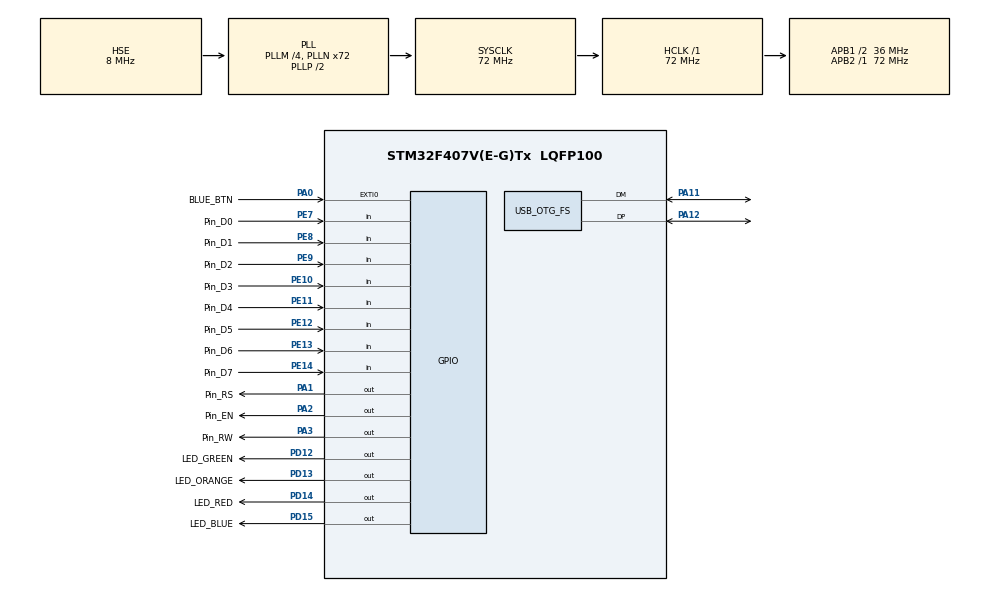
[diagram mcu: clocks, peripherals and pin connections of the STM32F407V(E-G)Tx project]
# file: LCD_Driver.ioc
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Mcu.Family=STM32F4
Mcu.Name=STM32F407V(E-G)Tx
Mcu.Package=LQFP100
NVIC.OTG_FS_IRQn=true\:0\:0\:false\:false\:true\:true\:true\:true
NVIC.PriorityGroup=NVIC_PRIORITYGROUP_0
PA0-WKUP.GPIO_Label=BLUE_BTN
PA0-WKUP.GPIO_ModeDefaultEXTI=GPIO_MODE_EVT_RISING
PA0-WKUP.GPIO_PuPd=GPIO_NOPULL
PA0-WKUP.Signal=GPXTI0
PA1.GPIO_Label=Pin_RS
PA1.Signal=GPIO_Output
PA11.Mode=Device_Only
PA11.Signal=USB_OTG_FS_DM
PA12.Mode=Device_Only
PA12.Signal=USB_OTG_FS_DP
PA2.GPIO_Label=Pin_EN
PA2.Signal=GPIO_Output
PA3.GPIO_Label=Pin_RW
PA3.Signal=GPIO_Output
PD12.GPIO_Label=LED_GREEN
PD12.GPIO_PuPd=GPIO_NOPULL
PD12.GPIO_Speed=GPIO_SPEED_FREQ_LOW
PD12.Signal=GPIO_Output
PD13.GPIO_Label=LED_ORANGE
PD13.GPIO_PuPd=GPIO_NOPULL
PD13.GPIO_Speed=GPIO_SPEED_FREQ_LOW
PD13.Signal=GPIO_Output
PD14.GPIO_Label=LED_RED
PD14.GPIO_PuPd=GPIO_NOPULL
PD14.GPIO_Speed=GPIO_SPEED_FREQ_LOW
PD14.Signal=GPIO_Output
PD15.GPIO_Label=LED_BLUE
PD15.GPIO_PuPd=GPIO_NOPULL
PD15.GPIO_Speed=GPIO_SPEED_FREQ_LOW
PD15.Signal=GPIO_Output
PE10.GPIO_Label=Pin_D3
PE10.Signal=GPIO_Input
PE11.GPIO_Label=Pin_D4
PE11.Signal=GPIO_Input
PE12.GPIO_Label=Pin_D5
PE12.Signal=GPIO_Input
PE13.GPIO_Label=Pin_D6
PE13.Signal=GPIO_Input
PE14.GPIO_Label=Pin_D7
PE14.Signal=GPIO_Input
PE7.GPIO_Label=Pin_D0
PE7.Signal=GPIO_Input
PE8.GPIO_Label=Pin_D1
PE8.Signal=GPIO_Input
PE9.GPIO_Label=Pin_D2
PE9.Signal=GPIO_Input
PH0-OSC_IN.Mode=HSE-External-Oscillator
PH0-OSC_IN.Signal=RCC_OSC_IN
PH1-OSC_OUT.Mode=HSE-External-Oscillator
PH1-OSC_OUT.Signal=RCC_OSC_OUT
ProjectManager.HeapSize=0x200
ProjectManager.StackSize=0x400
ProjectManager.TargetToolchain=STM32CubeIDE
RCC.48MHZClocksFreq_Value=48000000
RCC.AHBFreq_Value=72000000
RCC.APB1CLKDivider=RCC_HCLK_DIV2
RCC.APB1Freq_Value=36000000
RCC.APB1TimFreq_Value=72000000
RCC.APB2Freq_Value=72000000
RCC.APB2TimFreq_Value=72000000
RCC.CortexFreq_Value=72000000
RCC.HCLKFreq_Value=72000000
RCC.HSE_VALUE=8000000
RCC.HSI_VALUE=16000000
RCC.LSE_VALUE=32768
RCC.PLLM=4
RCC.PLLN=72
RCC.PLLQ=3
RCC.SYSCLKFreq_VALUE=72000000
RCC.SYSCLKSource=RCC_SYSCLKSOURCE_PLLCLK
RCC.VCOOutputFreq_Value=144000000
USB_DEVICE.CLASS_NAME_FS=CDC
USB_DEVICE.VirtualMode-CDC_FS=Cdc
USB_DEVICE.VirtualModeFS=Cdc_FS
USB_OTG_FS.VirtualMode=Device_Only
VP_USB_DEVICE_VS_USB_DEVICE_CDC_FS.Mode=CDC_FS
board=STM32F407G-DISC1

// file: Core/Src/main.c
/* USER CODE BEGIN Header */
/**
  ******************************************************************************
  * @file           : main.c
  * @brief          : Main program body
  ******************************************************************************
  * @attention
  *
  * Copyright (c) 2026 STMicroelectronics.
  * All rights reserved.
  *
  * This software is licensed under terms that can be found in the LICENSE file
  * in the root directory of this software component.
  * If no LICENSE file comes with this software, it is provided AS-IS.
  *
  ******************************************************************************
  */
/* USER CODE END Header */
#include <lcd_HD44780U.h>
#include "main.h"
#include "usb_device.h"

/* USER CODE BEGIN Includes */
#include <string.h>
#include "usbd_cdc_if.h"
/* USER CODE END Includes */

void SystemClock_Config(void);
static void MX_GPIO_Init(void);
/* USER CODE BEGIN PFP */
void USBD_CDC_Receive(uint8_t* buf, uint32_t* len);
/* USER CODE END PFP */

/* USER CODE BEGIN 0 */
void USBD_CDC_Receive(uint8_t* buf, uint32_t* len)
{
	//IMPORTANT: This function is run in an interrupt. Do not call HAL_Delay, any
	//other blocking operation or any heavy processing. For any of these, best course
	//of action is to copy the result into a buffer and process it in main(). For light
	//processing, doing it in this function is fine.
	CDC_Transmit_FS(buf, *len);
}

/* USER CODE END 0 */

int main(void)
{

  /* MCU Configuration--------------------------------------------------------*/

  /* Reset of all peripherals, Initializes the Flash interface and the Systick. */
  HAL_Init();

  /* Configure the system clock */
  SystemClock_Config();

  /* Initialize all configured peripherals */
  MX_GPIO_Init();
  MX_USB_DEVICE_Init();

  /* Infinite loop */
  /* USER CODE BEGIN WHILE */

  Init16x2LCD();

  while (1)
  {
    /* USER CODE END WHILE */

  }
}

void SystemClock_Config(void)
{
  RCC_OscInitTypeDef RCC_OscInitStruct = {0};
  RCC_ClkInitTypeDef RCC_ClkInitStruct = {0};

  /** Configure the main internal regulator output voltage
  */
  __HAL_RCC_PWR_CLK_ENABLE();
  __HAL_PWR_VOLTAGESCALING_CONFIG(PWR_REGULATOR_VOLTAGE_SCALE1);

  /** Initializes the RCC Oscillators according to the specified parameters
  * in the RCC_OscInitTypeDef structure.
  */
  RCC_OscInitStruct.OscillatorType = RCC_OSCILLATORTYPE_HSE;
  RCC_OscInitStruct.HSEState = RCC_HSE_ON;
  RCC_OscInitStruct.PLL.PLLState = RCC_PLL_ON;
  RCC_OscInitStruct.PLL.PLLSource = RCC_PLLSOURCE_HSE;
  RCC_OscInitStruct.PLL.PLLM = 4;
  RCC_OscInitStruct.PLL.PLLN = 72;
  RCC_OscInitStruct.PLL.PLLP = RCC_PLLP_DIV2;
  RCC_OscInitStruct.PLL.PLLQ = 3;
  if (HAL_RCC_OscConfig(&RCC_OscInitStruct) != HAL_OK)
  {
    Error_Handler();
  }

  /** Initializes the CPU, AHB and APB buses clocks
  */
  RCC_ClkInitStruct.ClockType = RCC_CLOCKTYPE_HCLK|RCC_CLOCKTYPE_SYSCLK
                              |RCC_CLOCKTYPE_PCLK1|RCC_CLOCKTYPE_PCLK2;
  RCC_ClkInitStruct.SYSCLKSource = RCC_SYSCLKSOURCE_PLLCLK;
  RCC_ClkInitStruct.AHBCLKDivider = RCC_SYSCLK_DIV1;
  RCC_ClkInitStruct.APB1CLKDivider = RCC_HCLK_DIV2;
  RCC_ClkInitStruct.APB2CLKDivider = RCC_HCLK_DIV1;

  if (HAL_RCC_ClockConfig(&RCC_ClkInitStruct, FLASH_LATENCY_2) != HAL_OK)
  {
    Error_Handler();
  }
}

static void MX_GPIO_Init(void)
{
  GPIO_InitTypeDef GPIO_InitStruct = {0};

  /* GPIO Ports Clock Enable */
  __HAL_RCC_GPIOH_CLK_ENABLE();
  __HAL_RCC_GPIOA_CLK_ENABLE();
  __HAL_RCC_GPIOE_CLK_ENABLE();
  __HAL_RCC_GPIOD_CLK_ENABLE();

  /*Configure GPIO pin Output Level */
  HAL_GPIO_WritePin(GPIOA, Pin_RS_Pin|Pin_EN_Pin|Pin_RW_Pin, GPIO_PIN_RESET);

  /*Configure GPIO pin Output Level */
  HAL_GPIO_WritePin(GPIOD, LED_GREEN_Pin|LED_ORANGE_Pin|LED_RED_Pin|LED_BLUE_Pin, GPIO_PIN_RESET);

  /*Configure GPIO pin : BLUE_BTN_Pin */
  GPIO_InitStruct.Pin = BLUE_BTN_Pin;
  GPIO_InitStruct.Mode = GPIO_MODE_EVT_RISING;
  GPIO_InitStruct.Pull = GPIO_NOPULL;
  HAL_GPIO_Init(BLUE_BTN_GPIO_Port, &GPIO_InitStruct);

  /*Configure GPIO pins : Pin_RS_Pin Pin_EN_Pin Pin_RW_Pin */
  GPIO_InitStruct.Pin = Pin_RS_Pin|Pin_EN_Pin|Pin_RW_Pin;
  GPIO_InitStruct.Mode = GPIO_MODE_OUTPUT_PP;
  GPIO_InitStruct.Pull = GPIO_NOPULL;
  GPIO_InitStruct.Speed = GPIO_SPEED_FREQ_LOW;
  HAL_GPIO_Init(GPIOA, &GPIO_InitStruct);

  /*Configure GPIO pins : Pin_D0_Pin Pin_D1_Pin Pin_D2_Pin Pin_D3_Pin
                           Pin_D4_Pin Pin_D5_Pin Pin_D6_Pin Pin_D7_Pin */
  GPIO_InitStruct.Pin = Pin_D0_Pin|Pin_D1_Pin|Pin_D2_Pin|Pin_D3_Pin
                          |Pin_D4_Pin|Pin_D5_Pin|Pin_D6_Pin|Pin_D7_Pin;
  GPIO_InitStruct.Mode = GPIO_MODE_INPUT;
  GPIO_InitStruct.Pull = GPIO_NOPULL;
  HAL_GPIO_Init(GPIOE, &GPIO_InitStruct);

  /*Configure GPIO pins : LED_GREEN_Pin LED_ORANGE_Pin LED_RED_Pin LED_BLUE_Pin */
  GPIO_InitStruct.Pin = LED_GREEN_Pin|LED_ORANGE_Pin|LED_RED_Pin|LED_BLUE_Pin;
  GPIO_InitStruct.Mode = GPIO_MODE_OUTPUT_PP;
  GPIO_InitStruct.Pull = GPIO_NOPULL;
  GPIO_InitStruct.Speed = GPIO_SPEED_FREQ_LOW;
  HAL_GPIO_Init(GPIOD, &GPIO_InitStruct);

}

void Error_Handler(void)
{
  __disable_irq();
  while (1)
  {
  }
}
